# STM32F107xC register map
File version: 1.0
Registers are 32-bit, read-write, reset 0x0 unless marked. A register's access mark holds for its fields unless they carry their own. Offsets are from the block's base; [hi:lo] are bit positions; {n}, {i} and the like mark numbered series.

## FLASH — FLASH Registers
Base 0x40022000
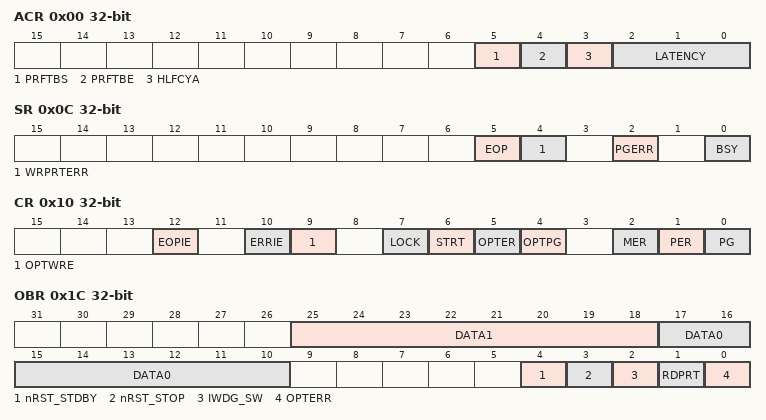
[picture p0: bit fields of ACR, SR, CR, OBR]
0x00 ACR
  [5] PRFTBS — Prefetch Buffer Status
  [4] PRFTBE — Prefetch Buffer Enable
  [3] HLFCYA — Flash Half Cycle Access Enable
  [2:0] LATENCY — LATENCY[2:0] bits (Latency)
    0=FLASH Zero Latency cycle; 1=FLASH One Latency cycle; 2=FLASH Two wait states
0x04 KEYR
  [31:0] FKEYR — FPEC Key
0x08 OPTKEYR
  [31:0] OPTKEYR — Option Byte Key
0x0C SR
  [5] EOP — End of operation
  [4] WRPRTERR — Write Protection Error
  [2] PGERR — Programming Error
  [0] BSY — Busy
0x10 CR
  [12] EOPIE — End of operation interrupt enable
  [10] ERRIE — Error Interrupt Enable
  [9] OPTWRE — Option Bytes Write Enable
  [7] LOCK
  [6] STRT — Start
  [5] OPTER — Option Byte Erase
  [4] OPTPG — Option Byte Programming
  [2] MER — Mass Erase
  [1] PER — Page Erase
  [0] PG — Programming
0x14 AR
  [31:0] FAR — Flash Address
0x1C OBR
  [25:18] DATA1
  [17:10] DATA0
  [4] nRST_STDBY
  [3] nRST_STOP
  [2] IWDG_SW
  [1] RDPRT — Read protection
  [0] OPTERR — Option Byte Error
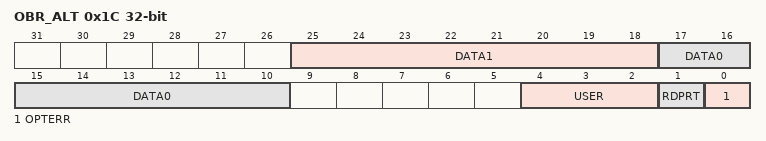
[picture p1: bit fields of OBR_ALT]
0x1C OBR_ALT (alternate view of OBR)
  [25:18] DATA1
  [17:10] DATA0
  [4:2] USER — User Option Bytes
  [1] RDPRT — Read protection
  [0] OPTERR — Option Byte Error
0x20 WRPR
  [31:0] WRP — Write Protect

## CRC — CRC calculation unit
Base 0x40023000
0x00 DR — CRC Data register
  [31:0] DR — Data register bits
0x04 IDR 8-bit — CRC Independent data register
  [7:0] IDR — General-purpose 8-bit data register bits
0x08 CR — CRC Control register
  [0] RESET — RESET bit

## ETH — Ethernet MAC
Base 0x40028000
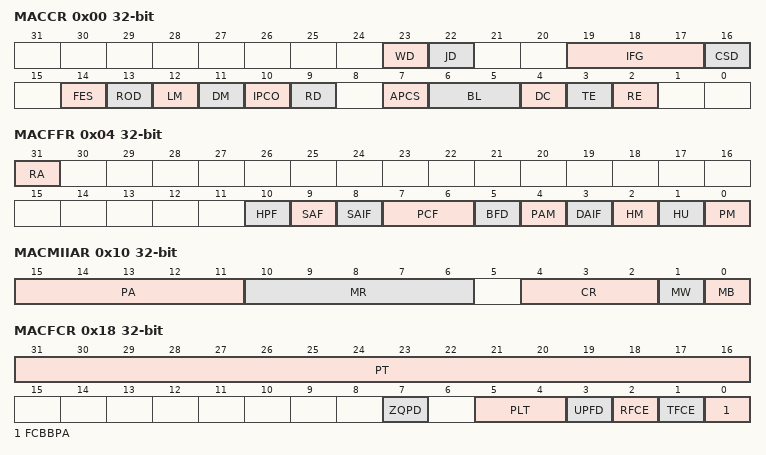
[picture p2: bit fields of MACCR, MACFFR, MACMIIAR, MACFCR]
0x00 MACCR
  [23] WD, [22] JD, [19:17] IFG, [16] CSD, [14] FES, [13] ROD, [12] LM, [11] DM, [10] IPCO, [9] RD, [7] APCS, [6:5] BL, [4] DC, [3] TE, [2] RE
0x04 MACFFR
  [31] RA, [10] HPF, [9] SAF, [8] SAIF, [7:6] PCF, [5] BFD, [4] PAM, [3] DAIF, [2] HM, [1] HU, [0] PM
0x08 MACHTHR
  [31:0] HTH
0x0C MACHTLR
  [31:0] HTL
0x10 MACMIIAR
  [15:11] PA, [10:6] MR, [4:2] CR, [1] MW, [0] MB
0x14 MACMIIDR
  [15:0] MD
0x18 MACFCR
  [31:16] PT, [7] ZQPD, [5:4] PLT, [3] UPFD, [2] RFCE, [1] TFCE, [0] FCBBPA
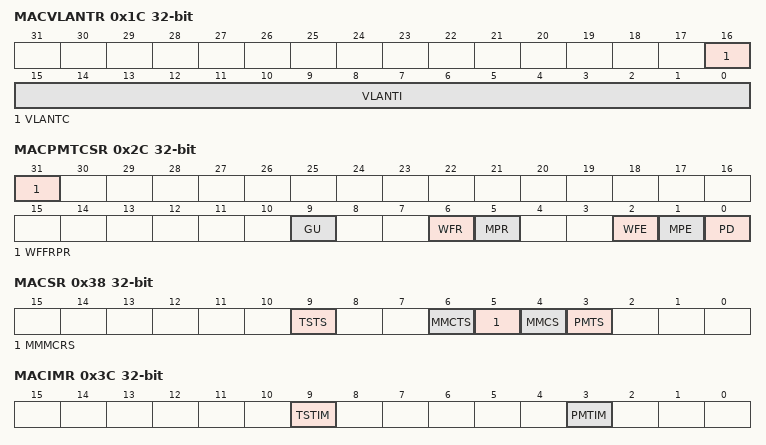
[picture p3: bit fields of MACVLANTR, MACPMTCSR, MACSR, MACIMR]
0x1C MACVLANTR
  [16] VLANTC, [15:0] VLANTI
0x28 MACRWUFFR
  [31:0] D
0x2C MACPMTCSR
  [31] WFFRPR, [9] GU, [6] WFR, [5] MPR, [2] WFE, [1] MPE, [0] PD
0x38 MACSR
  [9] TSTS, [6] MMCTS, [5] MMMCRS, [4] MMCS, [3] PMTS
0x3C MACIMR
  [9] TSTIM, [3] PMTIM
0x40 MACA0HR
  [15:0] MACA0H
{0x44+8i} MACA{i}LR (i=0..3)
  [31:0] MACA{i}L
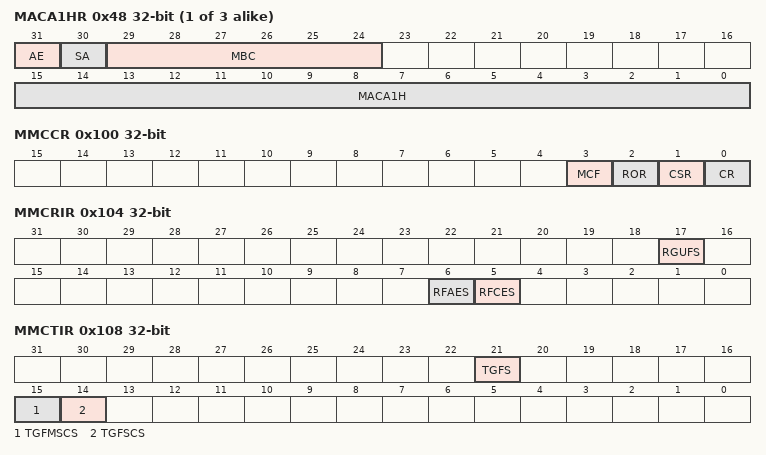
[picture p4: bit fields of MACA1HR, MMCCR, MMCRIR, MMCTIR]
{0x40+8i} MACA{i}HR (i=1..3)
  [31] AE, [30] SA, [29:24] MBC, [15:0] MACA{i}H
0x100 MMCCR
  [3] MCF, [2] ROR, [1] CSR, [0] CR
0x104 MMCRIR
  [17] RGUFS, [6] RFAES, [5] RFCES
0x108 MMCTIR
  [21] TGFS, [15] TGFMSCS, [14] TGFSCS
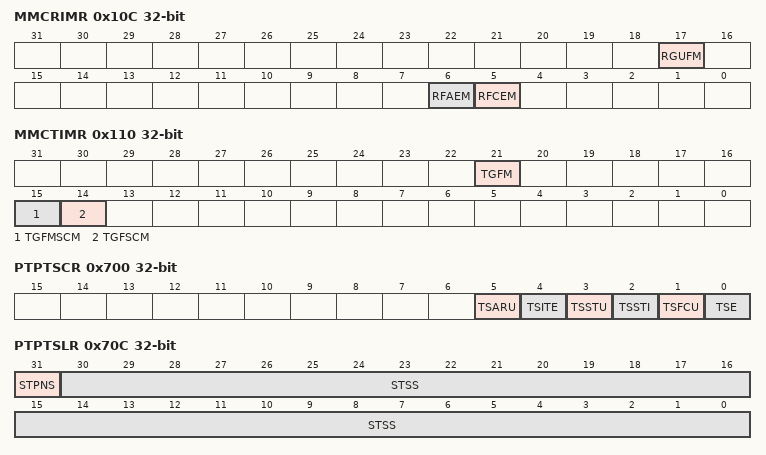
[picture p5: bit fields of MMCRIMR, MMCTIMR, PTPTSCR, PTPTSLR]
0x10C MMCRIMR
  [17] RGUFM, [6] RFAEM, [5] RFCEM
0x110 MMCTIMR
  [21] TGFM, [15] TGFMSCM, [14] TGFSCM
0x14C MMCTGFSCCR
  [31:0] TGFSCC
0x150 MMCTGFMSCCR
  [31:0] TGFMSCC
0x168 MMCTGFCR
  [31:0] TGFC
0x194 MMCRFCECR
  [31:0] RFCEC
0x198 MMCRFAECR
  [31:0] RFAEC
0x1C4 MMCRGUFCR
  [31:0] RGUFC
0x700 PTPTSCR
  [5] TSARU, [4] TSITE, [3] TSSTU, [2] TSSTI, [1] TSFCU, [0] TSE
0x704 PTPSSIR
  [7:0] STSSI
0x708 PTPTSHR
  [31:0] STS
0x70C PTPTSLR
  [31] STPNS, [30:0] STSS
0x710 PTPTSHUR
  [31:0] TSUS
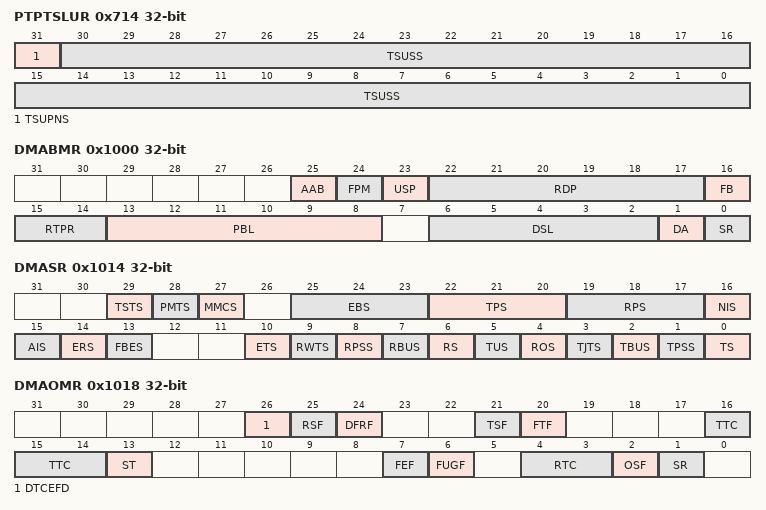
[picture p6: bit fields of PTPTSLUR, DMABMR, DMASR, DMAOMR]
0x714 PTPTSLUR
  [31] TSUPNS, [30:0] TSUSS
0x718 PTPTSAR
  [31:0] TSA
0x71C PTPTTHR
  [31:0] TTSH
0x720 PTPTTLR
  [31:0] TTSL
0x1000 DMABMR
  [25] AAB, [24] FPM, [23] USP, [22:17] RDP, [16] FB, [15:14] RTPR, [13:8] PBL, [6:2] DSL, [1] DA, [0] SR
0x1004 DMATPDR
  [31:0] TPD
0x1008 DMARPDR
  [31:0] RPD
0x100C DMARDLAR
  [31:0] SRL
0x1010 DMATDLAR
  [31:0] STL
0x1014 DMASR
  [29] TSTS, [28] PMTS, [27] MMCS, [25:23] EBS, [22:20] TPS, [19:17] RPS, [16] NIS, [15] AIS, [14] ERS, [13] FBES, [10] ETS, [9] RWTS, [8] RPSS, [7] RBUS, [6] RS, [5] TUS, [4] ROS, [3] TJTS, [2] TBUS, [1] TPSS, [0] TS
0x1018 DMAOMR
  [26] DTCEFD, [25] RSF, [24] DFRF, [21] TSF, [20] FTF, [16:14] TTC, [13] ST, [7] FEF, [6] FUGF, [4:3] RTC, [2] OSF, [1] SR
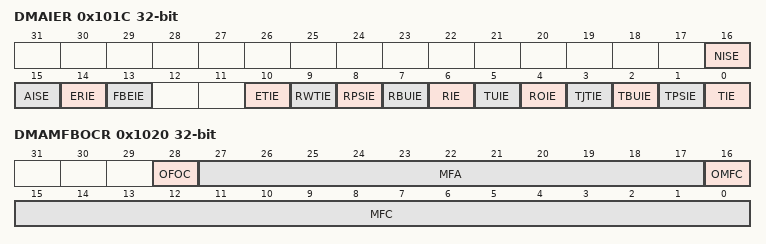
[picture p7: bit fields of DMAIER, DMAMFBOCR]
0x101C DMAIER
  [16] NISE, [15] AISE, [14] ERIE, [13] FBEIE, [10] ETIE, [9] RWTIE, [8] RPSIE, [7] RBUIE, [6] RIE, [5] TUIE, [4] ROIE, [3] TJTIE, [2] TBUIE, [1] TPSIE, [0] TIE
0x1020 DMAMFBOCR
  [28] OFOC, [27:17] MFA, [16] OMFC, [15:0] MFC
0x1048 DMACHTDR
  [31:0] HTDAP
0x104C DMACHRDR
  [31:0] HRDAP
0x1050 DMACHTBAR
  [31:0] HTBAP
0x1054 DMACHRBAR
  [31:0] HRBAP

## DBGMCU — Debug MCU
Base 0xE0042000
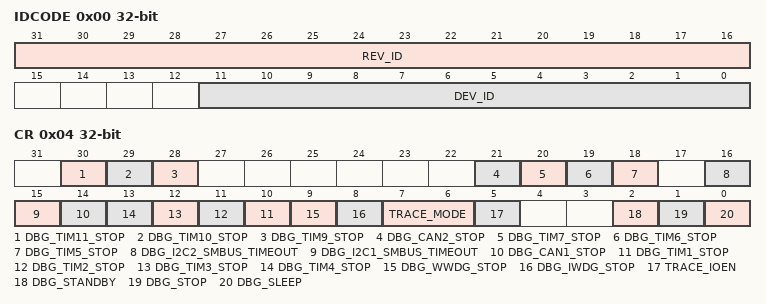
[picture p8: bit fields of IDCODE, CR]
0x00 IDCODE
  [31:16] REV_ID — REV_ID[15:0] bits (Revision Identifier)
  [11:0] DEV_ID — Device Identifier
0x04 CR
  [30] DBG_TIM11_STOP — Debug TIM11 stopped when Core is halted
  [29] DBG_TIM10_STOP — Debug TIM10 stopped when Core is halted
  [28] DBG_TIM9_STOP — Debug TIM9 stopped when Core is halted
  [21] DBG_CAN2_STOP — Debug CAN2 stopped when Core is halted
  [20] DBG_TIM7_STOP — TIM7 counter stopped when core is halted
  [19] DBG_TIM6_STOP — TIM6 counter stopped when core is halted
  [18] DBG_TIM5_STOP — TIM5 counter stopped when core is halted
  [16] DBG_I2C2_SMBUS_TIMEOUT — SMBUS timeout mode stopped when Core is halted
  [15] DBG_I2C1_SMBUS_TIMEOUT — SMBUS timeout mode stopped when Core is halted
  [14] DBG_CAN1_STOP — Debug CAN1 stopped when Core is halted
  [n+9] DBG_TIM{n}_STOP (n=1..4) — TIM{n} counter stopped when core is halted
  [9] DBG_WWDG_STOP — Debug Window Watchdog stopped when Core is halted
  [8] DBG_IWDG_STOP — Debug Independent Watchdog stopped when Core is halted
  [7:6] TRACE_MODE — TRACE_MODE[1:0] bits (Trace Pin Assignment Control)
  [5] TRACE_IOEN — Trace Pin Assignment Control
  [2] DBG_STANDBY — Debug Standby mode
  [1] DBG_STOP — Debug Stop Mode
  [0] DBG_SLEEP — Debug Sleep Mode
